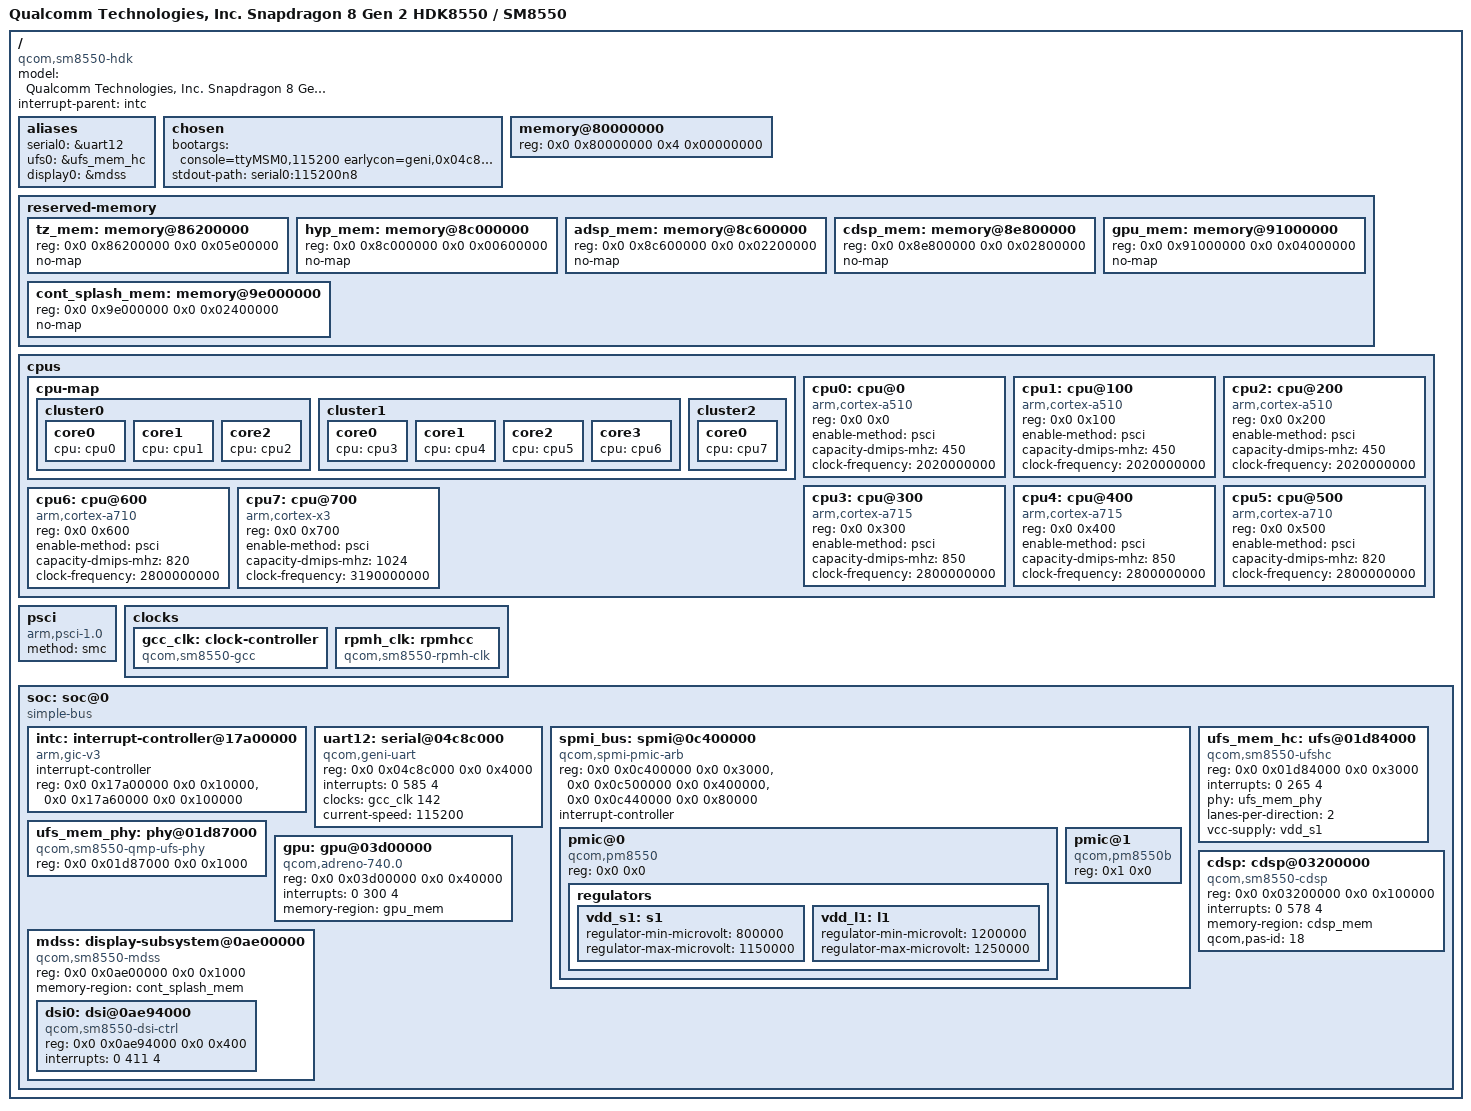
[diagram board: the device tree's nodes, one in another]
// PravahOS Device Tree Source for Qualcomm Snapdragon 8 Gen 2 / Gen 3 (SM8550 / HDK8550)
// Target: Qualcomm Snapdragon SM8550 Reference & Development Platform
/dts-v1/;

/memreserve/ 0x80000000 0x00010000;

/ {
	model = "Qualcomm Technologies, Inc. Snapdragon 8 Gen 2 HDK8550 / SM8550";
	compatible = "qcom,sm8550-hdk", "qcom,sm8550", "qcom,kalama";
	#address-cells = <2>;
	#size-cells = <2>;
	interrupt-parent = <&intc>;

	aliases {
		serial0 = &uart12;
		ufs0 = &ufs_mem_hc;
		display0 = &mdss;
	};

	chosen {
		bootargs = "console=ttyMSM0,115200 earlycon=geni,0x04c8c000 root=/dev/pravah_root init=/bin/init loglevel=7 pravah.platform=sm8550";
		stdout-path = "serial0:115200n8";
	};

	memory@80000000 {
		device_type = "memory";
		/* 16 GB LPDDR5X at base address 0x0000000080000000 */
		reg = <0x0 0x80000000 0x4 0x00000000>;
	};

	reserved-memory {
		#address-cells = <2>;
		#size-cells = <2>;
		ranges;

		tz_mem: memory@86200000 {
			reg = <0x0 0x86200000 0x0 0x05e00000>;
			no-map;
		};

		hyp_mem: memory@8c000000 {
			reg = <0x0 0x8c000000 0x0 0x00600000>;
			no-map;
		};

		adsp_mem: memory@8c600000 {
			reg = <0x0 0x8c600000 0x0 0x02200000>;
			no-map;
		};

		cdsp_mem: memory@8e800000 {
			/* Hexagon Compute DSP / NPU reserved SRAM/DRAM */
			reg = <0x0 0x8e800000 0x0 0x02800000>;
			no-map;
		};

		gpu_mem: memory@91000000 {
			/* Adreno 740 protected render target region */
			reg = <0x0 0x91000000 0x0 0x04000000>;
			no-map;
		};

		cont_splash_mem: memory@9e000000 {
			/* Continuous splash framebuffer handoff */
			reg = <0x0 0x9e000000 0x0 0x02400000>;
			no-map;
		};
	};

	cpus {
		#address-cells = <2>;
		#size-cells = <0>;

		/* Tri-cluster Kryo architecture: 1 Prime + 4 Gold (2x A715 + 2x A710) + 3 Silver */
		cpu-map {
			cluster0 {
				core0 {
					cpu = <&cpu0>;
				};
				core1 {
					cpu = <&cpu1>;
				};
				core2 {
					cpu = <&cpu2>;
				};
			};

			cluster1 {
				core0 {
					cpu = <&cpu3>;
				};
				core1 {
					cpu = <&cpu4>;
				};
				core2 {
					cpu = <&cpu5>;
				};
				core3 {
					cpu = <&cpu6>;
				};
			};

			cluster2 {
				core0 {
					cpu = <&cpu7>;
				};
			};
		};

		/* Kryo Silver cores (Cortex-A510 @ 2.02 GHz) */
		cpu0: cpu@0 {
			device_type = "cpu";
			compatible = "arm,cortex-a510", "arm,armv9";
			reg = <0x0 0x0>;
			enable-method = "psci";
			capacity-dmips-mhz = <450>;
			clock-frequency = <2020000000>;
		};

		cpu1: cpu@100 {
			device_type = "cpu";
			compatible = "arm,cortex-a510", "arm,armv9";
			reg = <0x0 0x100>;
			enable-method = "psci";
			capacity-dmips-mhz = <450>;
			clock-frequency = <2020000000>;
		};

		cpu2: cpu@200 {
			device_type = "cpu";
			compatible = "arm,cortex-a510", "arm,armv9";
			reg = <0x0 0x200>;
			enable-method = "psci";
			capacity-dmips-mhz = <450>;
			clock-frequency = <2020000000>;
		};

		/* Kryo Gold cores: 2x Cortex-A715 + 2x Cortex-A710 @ 2.80 GHz */
		cpu3: cpu@300 {
			device_type = "cpu";
			compatible = "arm,cortex-a715", "arm,armv9";
			reg = <0x0 0x300>;
			enable-method = "psci";
			capacity-dmips-mhz = <850>;
			clock-frequency = <2800000000>;
		};

		cpu4: cpu@400 {
			device_type = "cpu";
			compatible = "arm,cortex-a715", "arm,armv9";
			reg = <0x0 0x400>;
			enable-method = "psci";
			capacity-dmips-mhz = <850>;
			clock-frequency = <2800000000>;
		};

		cpu5: cpu@500 {
			device_type = "cpu";
			compatible = "arm,cortex-a710", "arm,armv9";
			reg = <0x0 0x500>;
			enable-method = "psci";
			capacity-dmips-mhz = <820>;
			clock-frequency = <2800000000>;
		};

		cpu6: cpu@600 {
			device_type = "cpu";
			compatible = "arm,cortex-a710", "arm,armv9";
			reg = <0x0 0x600>;
			enable-method = "psci";
			capacity-dmips-mhz = <820>;
			clock-frequency = <2800000000>;
		};

		/* Kryo Prime core: 1x Cortex-X3 @ 3.19 GHz */
		cpu7: cpu@700 {
			device_type = "cpu";
			compatible = "arm,cortex-x3", "arm,armv9";
			reg = <0x0 0x700>;
			enable-method = "psci";
			capacity-dmips-mhz = <1024>;
			clock-frequency = <3190000000>;
		};
	};

	psci {
		compatible = "arm,psci-1.0", "arm,psci-0.2";
		method = "smc";
	};

	clocks {
		gcc_clk: clock-controller {
			compatible = "qcom,sm8550-gcc";
			#clock-cells = <1>;
			#reset-cells = <1>;
		};

		rpmh_clk: rpmhcc {
			compatible = "qcom,sm8550-rpmh-clk";
			#clock-cells = <1>;
		};
	};

	soc: soc@0 {
		compatible = "simple-bus";
		#address-cells = <2>;
		#size-cells = <2>;
		ranges;

		/* ARM Generic Interrupt Controller v3 */
		intc: interrupt-controller@17a00000 {
			compatible = "arm,gic-v3";
			#interrupt-cells = <3>;
			interrupt-controller;
			reg = <0x0 0x17a00000 0x0 0x10000>,
			      <0x0 0x17a60000 0x0 0x100000>;
		};

		/* Qualcomm GENI Serial Engine (UART) */
		uart12: serial@04c8c000 {
			compatible = "qcom,geni-uart";
			reg = <0x0 0x04c8c000 0x0 0x4000>;
			interrupts = <0 585 4>;
			clock-names = "se";
			clocks = <&gcc_clk 142>;
			current-speed = <115200>;
			status = "okay";
		};

		/* Qualcomm SPMI PMIC Arbiter */
		spmi_bus: spmi@0c400000 {
			compatible = "qcom,spmi-pmic-arb";
			reg = <0x0 0x0c400000 0x0 0x3000>,
			      <0x0 0x0c500000 0x0 0x400000>,
			      <0x0 0x0c440000 0x0 0x80000>;
			reg-names = "core", "chnls", "obsrvr";
			#address-cells = <2>;
			#size-cells = <0>;
			interrupt-controller;
			#interrupt-cells = <4>;
			status = "okay";

			pmic@0 {
				reg = <0x0 0x0>;
				compatible = "qcom,pm8550";
				#address-cells = <1>;
				#size-cells = <0>;

				regulators {
					vdd_s1: s1 {
						regulator-min-microvolt = <800000>;
						regulator-max-microvolt = <1150000>;
					};
					vdd_l1: l1 {
						regulator-min-microvolt = <1200000>;
						regulator-max-microvolt = <1250000>;
					};
				};
			};

			pmic@1 {
				reg = <0x1 0x0>;
				compatible = "qcom,pm8550b";
				#address-cells = <1>;
				#size-cells = <0>;
			};
		};

		/* UFS 4.0 Storage Subsystem */
		ufs_mem_hc: ufs@01d84000 {
			compatible = "qcom,sm8550-ufshc", "jedec,ufs-2.0";
			reg = <0x0 0x01d84000 0x0 0x3000>;
			interrupts = <0 265 4>;
			phy = <&ufs_mem_phy>;
			lanes-per-direction = <2>;
			vcc-supply = <&vdd_s1>;
			status = "okay";
		};

		ufs_mem_phy: phy@01d87000 {
			compatible = "qcom,sm8550-qmp-ufs-phy";
			reg = <0x0 0x01d87000 0x0 0x1000>;
			#phy-cells = <0>;
			status = "okay";
		};

		/* Qualcomm Adreno 740 GPU */
		gpu: gpu@03d00000 {
			compatible = "qcom,adreno-740.0", "qcom,adreno";
			reg = <0x0 0x03d00000 0x0 0x40000>;
			interrupts = <0 300 4>;
			memory-region = <&gpu_mem>;
			status = "okay";
		};

		/* Qualcomm Hexagon Compute DSP / NPU */
		cdsp: cdsp@03200000 {
			compatible = "qcom,sm8550-cdsp", "qcom,q6v5-compute";
			reg = <0x0 0x03200000 0x0 0x100000>;
			interrupts = <0 578 4>;
			memory-region = <&cdsp_mem>;
			qcom,pas-id = <18>;
			status = "okay";
		};

		/* Mobile Display Subsystem (MDSS) / DPU */
		mdss: display-subsystem@0ae00000 {
			compatible = "qcom,sm8550-mdss";
			reg = <0x0 0x0ae00000 0x0 0x1000>;
			#address-cells = <2>;
			#size-cells = <2>;
			ranges;
			memory-region = <&cont_splash_mem>;
			status = "okay";

			dsi0: dsi@0ae94000 {
				compatible = "qcom,sm8550-dsi-ctrl", "qcom,mdss-dsi-ctrl";
				reg = <0x0 0x0ae94000 0x0 0x400>;
				interrupts = <0 411 4>;
				status = "okay";
			};
		};
	};
};
